# f29h85x_hsm_wdt0_regs register map
Vendor: Texas Instruments
Peripheral module from a debugger description file (folder HSM).
Registers are 32-bit, read-write, no defined reset value unless marked. A register's access mark holds for its fields unless they carry their own. Offsets are as the file gives them; lines under a group give offsets from that group; [hi:lo] are bit positions; {n}, {i} and the like mark numbered series; 'fields as' and 'values as' point back to an identical list; <NAME> marks a mode.

## HSM_WDT0 — HSM WDT0 Registers
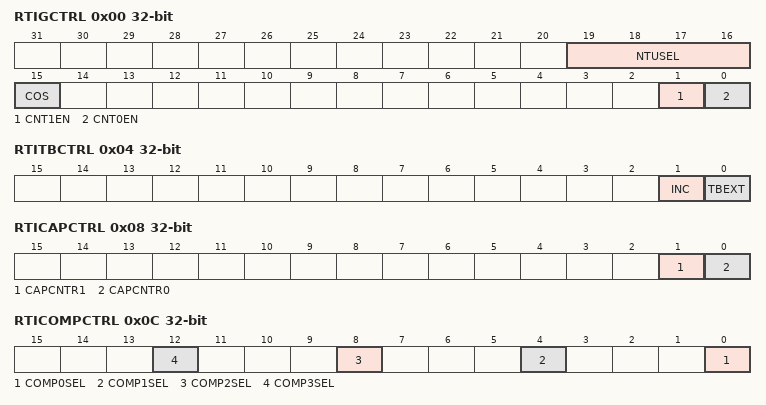
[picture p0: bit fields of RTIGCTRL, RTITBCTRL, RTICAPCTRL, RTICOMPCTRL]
0x00 RTIGCTRL
  [19:16] NTUSEL, [15] COS, [1] CNT1EN, [0] CNT0EN
0x04 RTITBCTRL
  [1] INC, [0] TBEXT
0x08 RTICAPCTRL
  [1] CAPCNTR1, [0] CAPCNTR0
0x0C RTICOMPCTRL
  [4n] COMP{n}SEL (n=0..3)
0x10 RTIFRC0
  [31:0] FRC0
0x14 RTIUC0
  [31:0] UC0
0x18 RTICPUC0
  [31:0] CPUC0
0x20 RTICAFRC0
  [31:0] CAFRC0
0x24 RTICAUC0
  [31:0] CAUC0
0x30 RTIFRC1
  [31:0] FRC1
0x34 RTIUC1
  [31:0] UC1
0x38 RTICPUC1
  [31:0] CPUC1
0x40 RTICAFRC1
  [31:0] CAFRC1
0x44 RTICAUC1
  [31:0] CAUC1
{0x50+8i} RTICOMP{i} (i=0..3)
  [31:0] COMP{i}
{0x54+8i} RTIUDCP{i} (i=0..3)
  [31:0] UDCP{i}
0x70 RTITBLCOMP
  [31:0] TBLCOMP
0x74 RTITBHCOMP
  [31:0] TBHCOMP
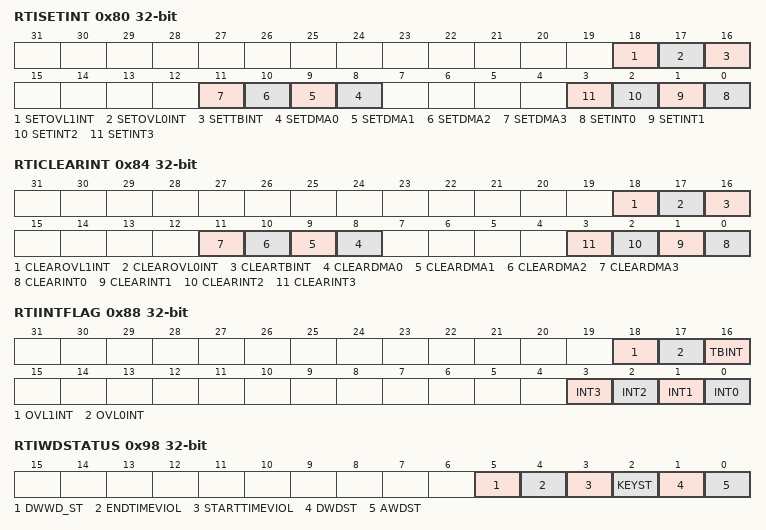
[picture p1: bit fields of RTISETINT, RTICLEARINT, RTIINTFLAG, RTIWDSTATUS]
0x80 RTISETINT
  [18] SETOVL1INT, [17] SETOVL0INT, [16] SETTBINT, [n+8] SETDMA{n} (n=0..3), [n] SETINT{n} (n=0..3)
0x84 RTICLEARINT
  [18] CLEAROVL1INT, [17] CLEAROVL0INT, [16] CLEARTBINT, [n+8] CLEARDMA{n} (n=0..3), [n] CLEARINT{n} (n=0..3)
0x88 RTIINTFLAG
  [18] OVL1INT, [17] OVL0INT, [16] TBINT, [n] INT{n} (n=0..3)
0x90 RTIDWDCTRL
  [31:0] DWDCTRL
0x94 RTIDWDPRLD
  [11:0] DWDPRLD
0x98 RTIWDSTATUS
  [5] DWWD_ST, [4] ENDTIMEVIOL, [3] STARTTIMEVIOL, [2] KEYST, [1] DWDST, [0] AWDST
0x9C RTIWDKEY
  [15:0] WDKEY
0xA0 RTIDWDCNTR
  [24:0] DWDCNTR
0xA4 RTIWWDRXNCTRL
  [3:0] WWDRXN
0xA8 RTIWWDSIZECTRL
  [31:0] WWDSIZE
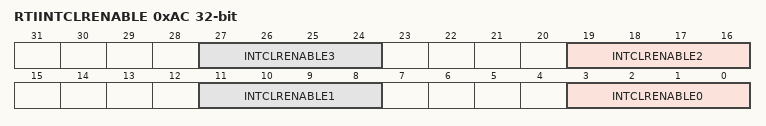
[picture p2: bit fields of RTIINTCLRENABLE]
0xAC RTIINTCLRENABLE
  [8n+3:8n] INTCLRENABLE{n} (n=0..3)
{0xB0+4i} RTICOMP{i}CLR (i=0..3)
  [31:0] COMP{i}CLR
